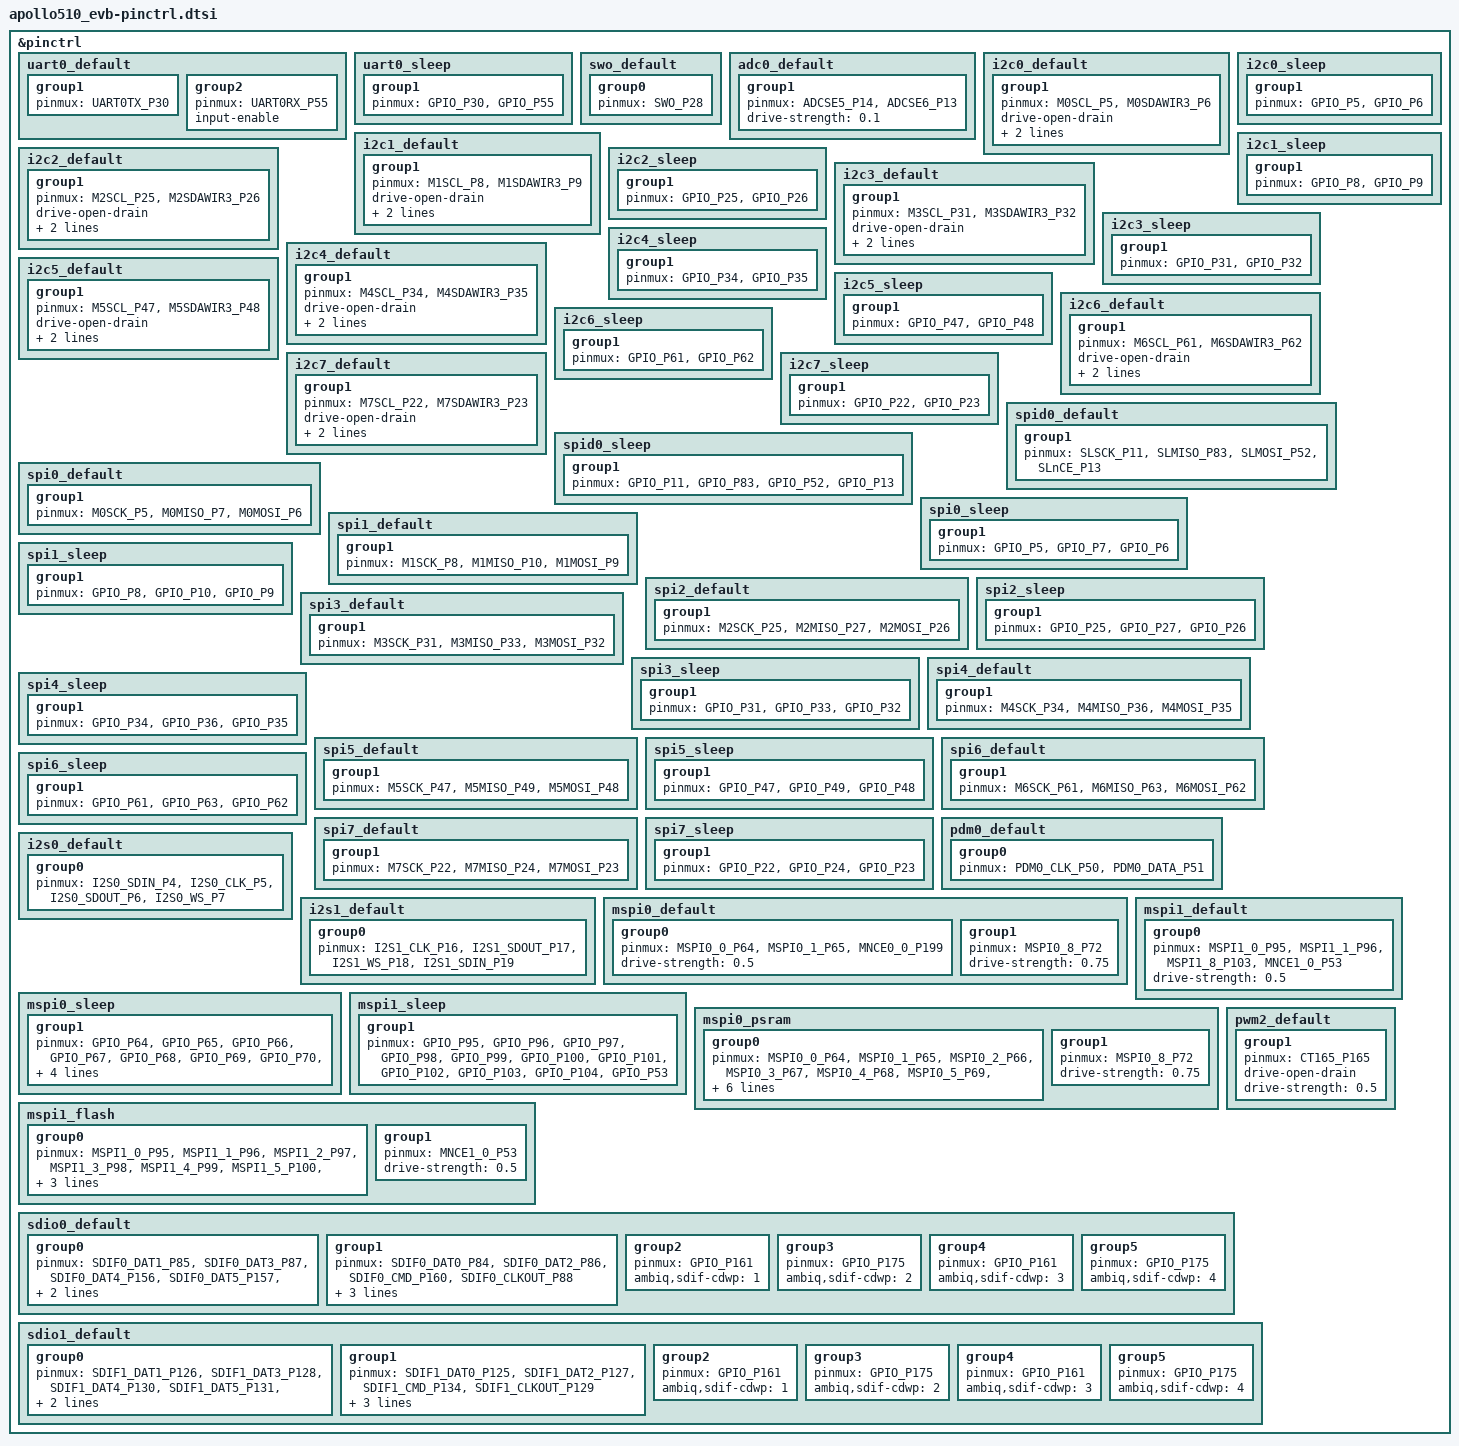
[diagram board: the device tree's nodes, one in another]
/*
 * Copyright (c) 2025 Ambiq Micro Inc.
 *
 * SPDX-License-Identifier: Apache-2.0
 */

#include <apollo510/ambiq-apollo510-pinmux.h>

&pinctrl {
	uart0_default: uart0_default {
		group1 {
			pinmux = <UART0TX_P30>;
		};

		group2 {
			pinmux = <UART0RX_P55>;
			input-enable;
		};
	};

	uart0_sleep: uart0_sleep {
		group1 {
			pinmux = <GPIO_P30>, <GPIO_P55>;
		};
	};

	swo_default: swo_default {
		group0 {
			pinmux = <SWO_P28>;
		};
	};

	adc0_default: adc0_default{
		group1 {
			pinmux = <ADCSE5_P14>, <ADCSE6_P13>;
			drive-strength = "0.1";
		};
	};

	i2c0_default: i2c0_default {
		group1 {
			pinmux = <M0SCL_P5>, <M0SDAWIR3_P6>;
			drive-open-drain;
			drive-strength = "0.5";
			bias-pull-up;
		};
	};

	i2c0_sleep: i2c0_sleep {
		group1 {
			pinmux = <GPIO_P5>, <GPIO_P6>;
		};
	};

	i2c1_default: i2c1_default {
		group1 {
			pinmux = <M1SCL_P8>, <M1SDAWIR3_P9>;
			drive-open-drain;
			drive-strength = "0.5";
			bias-pull-up;
		};
	};

	i2c1_sleep: i2c1_sleep {
		group1 {
			pinmux = <GPIO_P8>, <GPIO_P9>;
		};
	};

	i2c2_default: i2c2_default {
		group1 {
			pinmux = <M2SCL_P25>, <M2SDAWIR3_P26>;
			drive-open-drain;
			drive-strength = "0.5";
			bias-pull-up;
		};
	};

	i2c2_sleep: i2c2_sleep {
		group1 {
			pinmux = <GPIO_P25>, <GPIO_P26>;
		};
	};

	i2c3_default: i2c3_default {
		group1 {
			pinmux = <M3SCL_P31>, <M3SDAWIR3_P32>;
			drive-open-drain;
			drive-strength = "0.5";
			bias-pull-up;
		};
	};

	i2c3_sleep: i2c3_sleep {
		group1 {
			pinmux = <GPIO_P31>, <GPIO_P32>;
		};
	};

	i2c4_default: i2c4_default {
		group1 {
			pinmux = <M4SCL_P34>, <M4SDAWIR3_P35>;
			drive-open-drain;
			drive-strength = "0.5";
			bias-pull-up;
		};
	};

	i2c4_sleep: i2c4_sleep {
		group1 {
			pinmux = <GPIO_P34>, <GPIO_P35>;
		};
	};

	i2c5_default: i2c5_default {
		group1 {
			pinmux = <M5SCL_P47>, <M5SDAWIR3_P48>;
			drive-open-drain;
			drive-strength = "0.5";
			bias-pull-up;
		};
	};

	i2c5_sleep: i2c5_sleep {
		group1 {
			pinmux = <GPIO_P47>, <GPIO_P48>;
		};
	};

	i2c6_default: i2c6_default {
		group1 {
			pinmux = <M6SCL_P61>, <M6SDAWIR3_P62>;
			drive-open-drain;
			drive-strength = "0.5";
			bias-pull-up;
		};
	};

	i2c6_sleep: i2c6_sleep {
		group1 {
			pinmux = <GPIO_P61>, <GPIO_P62>;
		};
	};

	i2c7_default: i2c7_default {
		group1 {
			pinmux = <M7SCL_P22>, <M7SDAWIR3_P23>;
			drive-open-drain;
			drive-strength = "0.5";
			bias-pull-up;
		};
	};

	i2c7_sleep: i2c7_sleep {
		group1 {
			pinmux = <GPIO_P22>, <GPIO_P23>;
		};
	};

	spid0_default: spid0_default {
		group1 {
			pinmux = <SLSCK_P11>, <SLMISO_P83>, <SLMOSI_P52>, <SLnCE_P13>;
		};
	};

	spid0_sleep: spid0_sleep {
		group1 {
			pinmux = <GPIO_P11>, <GPIO_P83>, <GPIO_P52>, <GPIO_P13>;
		};
	};

	spi0_default: spi0_default {
		group1 {
			pinmux = <M0SCK_P5>, <M0MISO_P7>, <M0MOSI_P6>;
		};
	};

	spi0_sleep: spi0_sleep {
		group1 {
			pinmux = <GPIO_P5>, <GPIO_P7>, <GPIO_P6>;
		};
	};

	spi1_default: spi1_default {
		group1 {
			pinmux = <M1SCK_P8>, <M1MISO_P10>, <M1MOSI_P9>;
		};
	};

	spi1_sleep: spi1_sleep {
		group1 {
			pinmux = <GPIO_P8>, <GPIO_P10>, <GPIO_P9>;
		};
	};

	spi2_default: spi2_default {
		group1 {
			pinmux = <M2SCK_P25>, <M2MISO_P27>, <M2MOSI_P26>;
		};
	};

	spi2_sleep: spi2_sleep {
		group1 {
			pinmux = <GPIO_P25>, <GPIO_P27>, <GPIO_P26>;
		};
	};

	spi3_default: spi3_default {
		group1 {
			pinmux = <M3SCK_P31>, <M3MISO_P33>, <M3MOSI_P32>;
		};
	};

	spi3_sleep: spi3_sleep {
		group1 {
			pinmux = <GPIO_P31>, <GPIO_P33>, <GPIO_P32>;
		};
	};

	spi4_default: spi4_default {
		group1 {
			pinmux = <M4SCK_P34>, <M4MISO_P36>, <M4MOSI_P35>;
		};
	};

	spi4_sleep: spi4_sleep {
		group1 {
			pinmux = <GPIO_P34>, <GPIO_P36>, <GPIO_P35>;
		};
	};

	spi5_default: spi5_default {
		group1 {
			pinmux = <M5SCK_P47>, <M5MISO_P49>, <M5MOSI_P48>;
		};
	};

	spi5_sleep: spi5_sleep {
		group1 {
			pinmux = <GPIO_P47>, <GPIO_P49>, <GPIO_P48>;
		};
	};

	spi6_default: spi6_default {
		group1 {
			pinmux = <M6SCK_P61>, <M6MISO_P63>, <M6MOSI_P62>;
		};
	};

	spi6_sleep: spi6_sleep {
		group1 {
			pinmux = <GPIO_P61>, <GPIO_P63>, <GPIO_P62>;
		};
	};

	spi7_default: spi7_default {
		group1 {
			pinmux = <M7SCK_P22>, <M7MISO_P24>, <M7MOSI_P23>;
		};
	};

	spi7_sleep: spi7_sleep {
		group1 {
			pinmux = <GPIO_P22>, <GPIO_P24>, <GPIO_P23>;
		};
	};

	pdm0_default: pdm0_default {
		group0 {
			pinmux = <PDM0_CLK_P50>,
				 <PDM0_DATA_P51>;
		};
	};

	i2s0_default: i2s0_default {
		group0 {
			pinmux = <I2S0_SDIN_P4>,
				 <I2S0_CLK_P5>,
				 <I2S0_SDOUT_P6>,
				 <I2S0_WS_P7>;
		};
	};

	i2s1_default: i2s1_default {
		group0 {
			pinmux = <I2S1_CLK_P16>,
				 <I2S1_SDOUT_P17>,
				 <I2S1_WS_P18>,
				 <I2S1_SDIN_P19>;
		};
	};

	mspi0_default: mspi0_default {
		group0 {
			pinmux = <MSPI0_0_P64>,
				 <MSPI0_1_P65>,
				 <MNCE0_0_P199>;
			drive-strength = "0.5";
		};

		group1 {
			pinmux = <MSPI0_8_P72>;
			drive-strength = "0.75";
		};
	};

	mspi1_default: mspi1_default {
		group0 {
			pinmux = <MSPI1_0_P95>,
				 <MSPI1_1_P96>,
				 <MSPI1_8_P103>,
				 <MNCE1_0_P53>;
			drive-strength = "0.5";
		};
	};

	mspi0_sleep: mspi0_sleep {
		group1 {
			pinmux = <GPIO_P64>,
				 <GPIO_P65>,
				 <GPIO_P66>,
				 <GPIO_P67>,
				 <GPIO_P68>,
				 <GPIO_P69>,
				 <GPIO_P70>,
				 <GPIO_P71>,
				 <GPIO_P72>,
				 <GPIO_P73>,
				 <GPIO_P37>,
				 <GPIO_P38>,
				 <GPIO_P39>,
				 <GPIO_P40>,
				 <GPIO_P41>,
				 <GPIO_P42>,
				 <GPIO_P43>,
				 <GPIO_P44>,
				 <GPIO_P45>,
				 <GPIO_P199>;
		};
	};

	mspi1_sleep: mspi1_sleep {
		group1 {
			pinmux = <GPIO_P95>,
				 <GPIO_P96>,
				 <GPIO_P97>,
				 <GPIO_P98>,
				 <GPIO_P99>,
				 <GPIO_P100>,
				 <GPIO_P101>,
				 <GPIO_P102>,
				 <GPIO_P103>,
				 <GPIO_P104>,
				 <GPIO_P53>;
		};
	};

	mspi0_psram: mspi0_psram {
		group0 {
			pinmux = <MSPI0_0_P64>,   /* D0 */
				 <MSPI0_1_P65>,   /* D1 */
				 <MSPI0_2_P66>,   /* D2 */
				 <MSPI0_3_P67>,   /* D3 */
				 <MSPI0_4_P68>,   /* D4 */
				 <MSPI0_5_P69>,   /* D5 */
				 <MSPI0_6_P70>,   /* D6 */
				 <MSPI0_7_P71>,   /* D7 */
				 <MSPI0_9_P73>,   /* DQS0 */
				 <MSPI0_10_P37>,  /* D8 */
				 <MSPI0_11_P38>,  /* D9 */
				 <MSPI0_12_P39>,  /* D10 */
				 <MSPI0_13_P40>,  /* D11 */
				 <MSPI0_14_P41>,  /* D12 */
				 <MSPI0_15_P42>,  /* D13 */
				 <MSPI0_16_P43>,  /* D14 */
				 <MSPI0_17_P44>,  /* D15 */
				 <MSPI0_18_P45>,  /* DQS1 */
				 <MNCE0_0_P199>;  /* CE0 */
			drive-strength = "0.5";
		};

		group1 {
			pinmux = <MSPI0_8_P72>;   /* SCK */
			drive-strength = "0.75";
		};
	};

	mspi1_flash: mspi1_flash {
		group0 {
			pinmux = <MSPI1_0_P95>,
				 <MSPI1_1_P96>,
				 <MSPI1_2_P97>,
				 <MSPI1_3_P98>,
				 <MSPI1_4_P99>,
				 <MSPI1_5_P100>,
				 <MSPI1_6_P101>,
				 <MSPI1_7_P102>,
				 <MSPI1_8_P103>,
				 <MSPI1_9_P104>;
			drive-strength = "1.0";
		};

		group1 {
			pinmux = <MNCE1_0_P53>;
			drive-strength = "0.5";
		};
	};

	pwm2_default: pwm2_default{
		group1 {
			pinmux = <CT165_P165>;
			drive-open-drain;
			drive-strength = "0.5";
		};
	};

	sdio0_default: sdio0_default {
		group0 {
			pinmux = <SDIF0_DAT1_P85>,
				 <SDIF0_DAT3_P87>,
				 <SDIF0_DAT4_P156>,
				 <SDIF0_DAT5_P157>,
				 <SDIF0_DAT6_P158>,
				 <SDIF0_DAT7_P159>;
				 drive-strength = "1.0";
		};
		group1 {
			pinmux = <SDIF0_DAT0_P84>,
				 <SDIF0_DAT2_P86>,
				 <SDIF0_CMD_P160>,
				 <SDIF0_CLKOUT_P88>;
				 drive-strength = "1.0";
				 bias-pull-up;
				 ambiq,pull-up-ohms = <12000>;
		};
		group2 {
			pinmux = <GPIO_P161>;
				 ambiq,sdif-cdwp = <1>;
		};
		group3 {
			pinmux = <GPIO_P175>;
				 ambiq,sdif-cdwp = <2>;
		};
		group4 {
			pinmux = <GPIO_P161>;
				 ambiq,sdif-cdwp = <3>;
		};
		group5 {
			pinmux = <GPIO_P175>;
				 ambiq,sdif-cdwp = <4>;
		};
	};

	sdio1_default: sdio1_default {
		group0 {
			pinmux = <SDIF1_DAT1_P126>,
				 <SDIF1_DAT3_P128>,
				 <SDIF1_DAT4_P130>,
				 <SDIF1_DAT5_P131>,
				 <SDIF1_DAT6_P132>,
				 <SDIF1_DAT7_P133>;
				 drive-strength = "1.0";
		};
		group1 {
			pinmux = <SDIF1_DAT0_P125>,
				 <SDIF1_DAT2_P127>,
				 <SDIF1_CMD_P134>,
				 <SDIF1_CLKOUT_P129>;
				 drive-strength = "1.0";
				 bias-pull-up;
				 ambiq,pull-up-ohms = <12000>;
		};
		group2 {
			pinmux = <GPIO_P161>;
				 ambiq,sdif-cdwp = <1>;
		};
		group3 {
			pinmux = <GPIO_P175>;
				 ambiq,sdif-cdwp = <2>;
		};
		group4 {
			pinmux = <GPIO_P161>;
				 ambiq,sdif-cdwp = <3>;
		};
		group5 {
			pinmux = <GPIO_P175>;
				 ambiq,sdif-cdwp = <4>;
		};
	};
};
